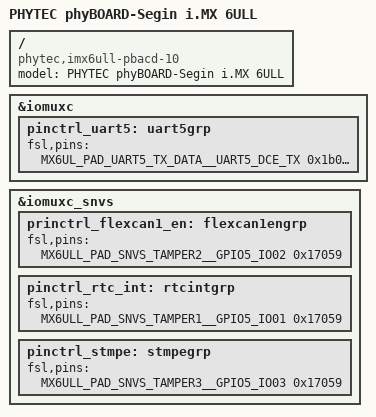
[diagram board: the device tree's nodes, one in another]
// SPDX-License-Identifier: (GPL-2.0+ OR MIT)
/*
 * Copyright (C) 2018 PHYTEC Messtechnik GmbH
 * Author: Stefan Riedmueller <s.riedmueller@phytec.de>
 */

#include "imx6ul-phytec-segin.dtsi"

/ {
	model = "PHYTEC phyBOARD-Segin i.MX 6ULL";
	compatible = "phytec,imx6ull-pbacd-10", "phytec,imx6ull-pcl063","fsl,imx6ull";
};

&iomuxc {
	/delete-node/ flexcan1engrp;
	/delete-node/ rtcintgrp;
	/delete-node/ stmpegrp;
	/delete-node/ uart5grp;
};

&iomuxc_snvs {
	princtrl_flexcan1_en: flexcan1engrp {
		fsl,pins = <
			MX6ULL_PAD_SNVS_TAMPER2__GPIO5_IO02	0x17059
		>;
	};

	pinctrl_rtc_int: rtcintgrp {
		fsl,pins = <
			MX6ULL_PAD_SNVS_TAMPER1__GPIO5_IO01	0x17059
		>;
	};

	pinctrl_stmpe: stmpegrp {
		fsl,pins = <
			MX6ULL_PAD_SNVS_TAMPER3__GPIO5_IO03	0x17059
		>;
	};
};

&iomuxc {
	pinctrl_uart5: uart5grp {
		fsl,pins = <
			MX6UL_PAD_UART5_TX_DATA__UART5_DCE_TX	0x1b0b1
			MX6ULL_PAD_UART5_RX_DATA__UART5_DCE_RX	0x1b0b1
			MX6UL_PAD_GPIO1_IO08__UART5_DCE_RTS	0x1b0b1
			MX6UL_PAD_GPIO1_IO09__UART5_DCE_CTS	0x1b0b1
		>;
	};
};
